# tviic2d6mddr register map
Vendor: Cypress Semiconductor; Series: tviic2d6mddr; File version: 1.0
CPU: CM7 r0p1, little endian, MPU, FPU, VTOR, 3 interrupt priority bits
Registers are 32-bit, read-write, reset 0x0 unless marked. A register's access mark holds for its fields unless they carry their own. Offsets are from the block's base; [hi:lo] are bit positions; lines under a group give offsets from that group; {n}, {i} and the like mark numbered series.

## LPDDR40 (part 3 of 5) — LPDDR4
Base 0x404A0000
0x1000 LPDDR4_CORE group — LPDDR4 core (3PIP)
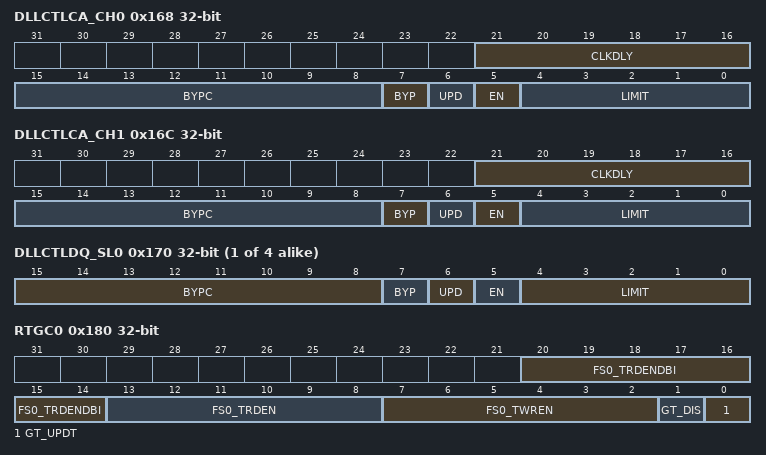
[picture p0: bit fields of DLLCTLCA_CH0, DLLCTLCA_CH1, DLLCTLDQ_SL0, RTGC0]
  0x168 DLLCTLCA_CH0 — DLL Control Register for PHY Command Module - Channel 0
    [21:16] CLKDLY — Phase shifting for mem_clk 6'b000000: No shifted 6'b111111: 0.5 cycle - Channel 0
    [15:8] BYPC — DLL bypass code. - Channel 0
    [7] BYP — DLL bypass enable. - Channel 0 Enable/disable coding: DISABLE = 0 Disable this feature ENABLE = 1 Enable this feature
    [6] UPD — DLL Update. When the PHY is in active operation, DLL update should be turn off. - Channel 0 Enable/disable coding: DISABLE = 0 Disable this feature ENABLE = 1 Enable this feature
    [5] EN — DLL enable. - Channel 0 Enable/disable coding: DISABLE = 0 Disable this feature ENABLE = 1 Enable this feature
    [4:0] LIMIT — Bandwidth for the digital loop. - Channel 0 The recommended value from simulation is 5. The optimum value must be determined from evaluation.
  0x16C DLLCTLCA_CH1 — DLL Control Register for PHY Command Module - Channel 1
    [21:16] CLKDLY — Phase shifting for mem_clk 6'b000000: No shifted 6'b111111: 0.5 cycle - Channel 1
    [15:8] BYPC — DLL bypass code. - Channel 1
    [7] BYP — DLL bypass enable. - Channel 1 Enable/disable coding: DISABLE = 0 Disable this feature ENABLE = 1 Enable this feature
    [6] UPD — DLL Update. When the PHY is in active operation, DLL update should be turn off. - Channel 1 Enable/disable coding: DISABLE = 0 Disable this feature ENABLE = 1 Enable this feature
    [5] EN — DLL enable. - Channel 1 Enable/disable coding: DISABLE = 0 Disable this feature ENABLE = 1 Enable this feature
    [4:0] LIMIT — Bandwidth for the digital loop. - Channel 1 The recommended value from simulation is 5. The optimum value must be determined from evaluation.
  {0x170+4j} DLLCTLDQ_SL{j} (j=0..3) — DLL Control Register for PHY Data Module
    [15:8] BYPC — DLL bypass code.
    [7] BYP — DLL bypass enable. Enable/disable coding: DISABLE = 0 Disable this feature ENABLE = 1 Enable this feature
    [6] UPD — DLL Update. When the PHY is in active operation, DLL update should be turn off. Enable/disable coding: DISABLE = 0 Disable this feature ENABLE = 1 Enable this feature
    [5] EN — DLL enable. Enable/disable coding: DISABLE = 0 Disable this feature ENABLE = 1 Enable this feature
    [4:0] LIMIT — Bandwidth for the digital loop. The recommended value from simulation is 5. The optimum value must be determined from evaluation.
  0x180 RTGC0 — PHY Read Training General Control Register 0
    [20:14] FS0_TRDENDBI — Specifies the number of DFI PHY clock cycles from the assertion of a read command on the DFI to the assertion of the dfi_rddata_en signal in DBI mode
    [13:8] FS0_TRDEN — Specifies the number of DFI PHY clock cycles from the assertion of a read command on the DFI to the assertion of the dfi_rddata_en signal LPDDR4: RL-1
    [7:2] FS0_TWREN — Specifies the number of DFI PHY clock cycles between when a write command is sent on the DFI control interface and when the dfi_wrdata_en signal is asserted. LPDDR4: WL-1
    [1] GT_DIS — Auto gate training disable. This will disable automatic read gate enable. Enable/disable coding: ENABLE = 0 Enable this feature DISABLE = 1 Disable this feature
    [0] GT_UPDT — Gate training setting update Enable/disable coding: DISABLE = 0 Disable this feature ENABLE = 1 Enable this feature
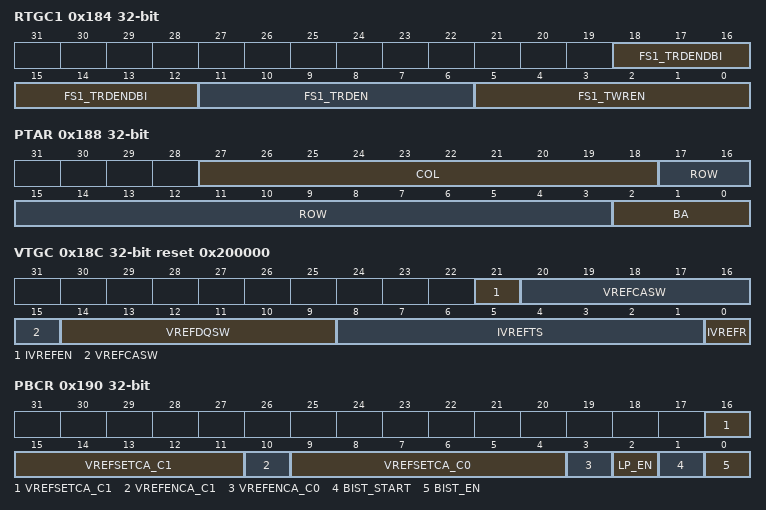
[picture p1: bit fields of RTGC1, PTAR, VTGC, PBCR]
  0x184 RTGC1 — PHY Read Training General Control Register 1
    [18:12] FS1_TRDENDBI — Specifies the number of DFI PHY clock cycles from the assertion of a read command on the DFI to the assertion of the dfi_rddata_en signal in DBI mode
    [11:6] FS1_TRDEN — Specifies the number of DFI PHY clock cycles from the assertion of a read command on the DFI to the assertion of the dfi_rddata_en signal LPDDR4: RL-1
    [5:0] FS1_TWREN — Specifies the number of DFI PHY clock cycles between when a write command is sent on the DFI control interface and when the dfi_wrdata_en signal is asserted. LPDDR4: WL-1
  0x188 PTAR — PHY Sanity Check Address Register
    [27:18] COL — Test column address to be used in Read-Write Sanity Check feature to test Read/Write functions after trainings. This feature is enabled by setting sanchken and phyinit field in POM register.
    [17:3] ROW — Test row address to be used in Read-Write Sanity Check feature to test Read/Write functions after trainings. This feature is enabled by setting sanchken and phyinit field in POM register.
    [2:0] BA — Test bank address to be used in Read-Write Sanity Check feature to test Read/Write functions after trainings. This feature is enabled by setting sanchken and phyinit field in POM register.
  0x18C VTGC reset 0x200000 — PHY VREF Training General Control Register
    [21] IVREFEN — Use Internal PHY VREF. Always set to 1'b1. ENABLE = 1 Always write 1.
    [20:15] VREFCASW — DRAM VREF-CA step width. This field defines the distance between 2 VREF steps in coarse training.
    [14:9] VREFDQSW — DRAM VREF-DQ step width. This field defines the distance between 2 VREF steps in coarse training.
    [8:1] IVREFTS — PHY VREF-DQ training step, specify the number training patterns required by PHY. STEPS64 = 64 Always write 64.
    [0] IVREFR — Internal PHY VREF-DQ range RANGE1 = 1 Always write 1.
  0x190 PBCR — PHY BIST Control Register
    [16:11] VREFSETCA_C1 — VREF setting for control block, in BIST/Loopback mode - Channel B
    [10] VREFENCA_C1 — VREF enable for control block, in BIST/Loopback mode - Channel B Enable/disable coding: DISABLE = 0 Disable this feature ENABLE = 1 Enable this feature
    [9:4] VREFSETCA_C0 — VREF setting for control block, in BIST/Loopback mode - Channel A
    [3] VREFENCA_C0 — VREF enable for control block, in BIST/Loopback mode - Channel A Enable/disable coding: DISABLE = 0 Disable this feature ENABLE = 1 Enable this feature
    [2] LP_EN — PHY Loopback mode enable Enable/disable coding: DISABLE = 0 Disable this feature ENABLE = 1 Enable this feature
    [1] BIST_START — Start PHY BIST mode Enable/disable coding: DISABLE = 0 Disable this feature ENABLE = 1 Enable this feature
    [0] BIST_EN — PHY BIST mode enable Enable/disable coding: DISABLE = 0 Disable this feature ENABLE = 1 Enable this feature
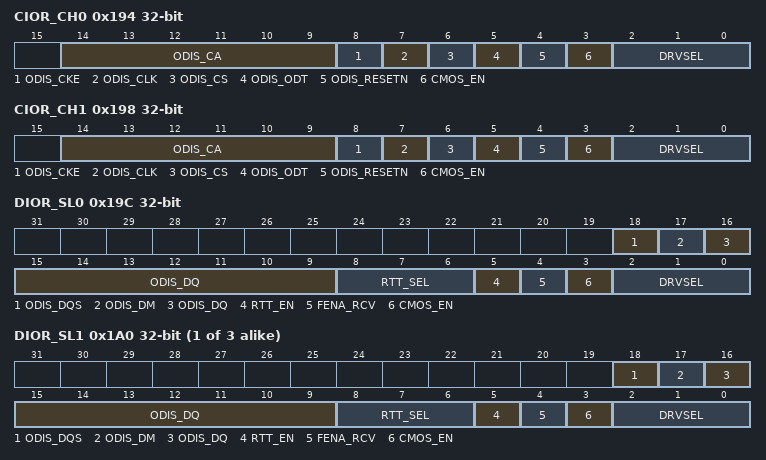
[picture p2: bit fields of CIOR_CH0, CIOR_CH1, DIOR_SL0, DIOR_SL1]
  0x194 CIOR_CH0 — PHY Command Module IO Control Register - Channel 0
    [14:9] ODIS_CA — Channel 0 mem_ca Output Driver Disable. When set to 1, the corresponding output is forced to high-Z. NORMAL = 0 Normal operation FORCE_HIZ = 1 Forced to high-Z
    [8] ODIS_CKE — Channel 0 mem_cke Output Driver Disable. When set to 1, the corresponding output is forced to high-Z. NORMAL = 0 Normal operation FORCE_HIZ = 1 Forced to high-Z
    [7] ODIS_CLK — Channel 0 mem_clk Output Driver Disable. When set to 1, the corresponding output is forced to high-Z. NORMAL = 0 Normal operation FORCE_HIZ = 1 Forced to high-Z
    [6] ODIS_CS — Channel 0 mem_cs Output Driver Disable. When set to 1, the corresponding output is forced to high-Z. NORMAL = 0 Normal operation FORCE_HIZ = 1 Forced to high-Z
    [5] ODIS_ODT — Channel 0 mem_odt Output Driver Disable. When set to 1, the corresponding output is forced to high-Z. NORMAL = 0 Normal operation FORCE_HIZ = 1 Forced to high-Z
    [4] ODIS_RESETN — Channel 0 mem_reset Output Driver Disable. When set to 1, the corresponding output is forced to high-Z. NORMAL = 0 Normal operation FORCE_HIZ = 1 Forced to high-Z
    [3] CMOS_EN — Enable CMOS Receiver in IO - Channel 0 Enable/disable coding: DISABLE = 0 Disable this feature ENABLE = 1 Enable this feature
    [2:0] DRVSEL — 3-bit value to select how many copies of driver need to be turned on. Driver Setting (000-turns on 1 driver copy, 001- 2 driver copy, 010- 3 driver copy, 111- 8 driver copy) - Channel 0 Selects how many copies of drivers are turned on. Number of drivers: DRV1 = 000b 1 driver DRV2 = 001b 2 drivers DRV3 = 010b 3 drivers DRV4 = 011b 4 drivers DRV5 = 100b 5 drivers DRV6 = 101b 6 drivers DRV7 = 110b 7 drivers DRV8 = 111b 8 drivers
  0x198 CIOR_CH1 — PHY Command Module IO Control Register - Channel 1
    [14:9] ODIS_CA — Channel 1 mem_ca Output Driver Disable. When set to 1, the corresponding output is forced to high-Z. NORMAL = 0 Normal operation FORCE_HIZ = 1 Forced to high-Z
    [8] ODIS_CKE — Channel 1 mem_cke Output Driver Disable. When set to 1, the corresponding output is forced to high-Z. NORMAL = 0 Normal operation FORCE_HIZ = 1 Forced to high-Z
    [7] ODIS_CLK — Channel 1 mem_clk Output Driver Disable. When set to 1, the corresponding output is forced to high-Z. NORMAL = 0 Normal operation FORCE_HIZ = 1 Forced to high-Z
    [6] ODIS_CS — Channel 1 mem_cs Output Driver Disable. When set to 1, the corresponding output is forced to high-Z. NORMAL = 0 Normal operation FORCE_HIZ = 1 Forced to high-Z
    [5] ODIS_ODT — Channel 1 mem_odt Output Driver Disable. When set to 1, the corresponding output is forced to high-Z. NORMAL = 0 Normal operation FORCE_HIZ = 1 Forced to high-Z
    [4] ODIS_RESETN — Channel 0 mem_reset Output Driver Disable. When set to 1, the corresponding output is forced to high-Z. NORMAL = 0 Normal operation FORCE_HIZ = 1 Forced to high-Z
    [3] CMOS_EN — Enable CMOS Receiver in IO - Channel 1 Enable/disable coding: DISABLE = 0 Disable this feature ENABLE = 1 Enable this feature
    [2:0] DRVSEL — 3-bit value to select how many copies of driver need to be turned on. Driver Setting (000-turns on 1 driver copy, 001- 2 driver copy, 010- 3 driver copy, 111- 8 driver copy) - Channel 1 Selects how many copies of drivers are turned on. Number of drivers: DRV1 = 000b 1 driver DRV2 = 001b 2 drivers DRV3 = 010b 3 drivers DRV4 = 011b 4 drivers DRV5 = 100b 5 drivers DRV6 = 101b 6 drivers DRV7 = 110b 7 drivers DRV8 = 111b 8 drivers
  0x19C DIOR_SL0 — PHY Data Module IO Control Register
    [18] ODIS_DQS — Data Slice 0 DQS Output Driver Disable. When set to 1, the corresponding output is forced to high-Z. NORMAL = 0 Normal operation FORCE_HIZ = 1 Forced to high-Z
    [17] ODIS_DM — Data Slice 0 DM Output Driver Disable. When set to 1, the corresponding output is forced to high-Z. NORMAL = 0 Normal operation FORCE_HIZ = 1 Forced to high-Z
    [16:9] ODIS_DQ — Data Slice 0 DQ Output Driver Disable. When set to 1, the corresponding output is forced to high-Z. NORMAL = 0 Normal operation FORCE_HIZ = 1 Forced to high-Z
    [8:6] RTT_SEL — Data Slice 0 RTT impedance when rtt_en=1. Values according to JESD209-4: RTT240 = 001b RTT = 240Ohm RTT120 = 010b RTT = 120Ohm RTT80 = 011b RTT = 80Ohm RTT60 = 100b RTT = 60Ohm RTT48 = 101b RTT = 48Ohm RTT40 = 110b RTT = 40Ohm
    [5] RTT_EN — Enable On-Die Termination resistor RTT for slice 0. Enable/disable coding: DISABLE = 0 Disable this feature ENABLE = 1 Enable this feature
    [4] FENA_RCV — PHY Data Module IO Control Register for Slice 0. Driver output enable DRV_TRISTATE = 0 Driver in tristate DRV_ENABLE = 1 Driver enabled FENA_RCV has higher priority than ODIS and OE when it is high. Enable = FENA_RCV + !ODIS & OE
    [3] CMOS_EN — Enable CMOS Receiver in IO Enable/disable coding: DISABLE = 0 Disable this feature ENABLE = 1 Enable this feature
    [2:0] DRVSEL — PHY Data Module IO Control Register Slice 0. Selects how many copies of drivers are turned on. Number of drivers: DRV1 = 000b 1 driver DRV2 = 001b 2 drivers DRV3 = 010b 3 drivers DRV4 = 011b 4 drivers DRV5 = 100b 5 drivers DRV6 = 101b 6 drivers DRV7 = 110b 7 drivers DRV8 = 111b 8 drivers
  {0x19C+4j} DIOR_SL{j} (j=1..3) — PHY Data Module IO Control Register
    [18] ODIS_DQS — Data Slice {j} DQS Output Driver Disable. When set to 1, the corresponding output is forced to high-Z. NORMAL = 0 Normal operation FORCE_HIZ = 1 Forced to high-Z
    [17] ODIS_DM — Data Slice {j} DM Output Driver Disable. When set to 1, the corresponding output is forced to high-Z. NORMAL = 0 Normal operation FORCE_HIZ = 1 Forced to high-Z
    [16:9] ODIS_DQ — Data Slice {j} DQ Output Driver Disable. When set to 1, the corresponding output is forced to high-Z. NORMAL = 0 Normal operation FORCE_HIZ = 1 Forced to high-Z
    [8:6] RTT_SEL — Data Slice {j} RTT impedance when rtt_en=1. Values according to JESD209-4: RTT240 = 001b RTT = 240Ohm RTT120 = 010b RTT = 120Ohm RTT80 = 011b RTT = 80Ohm RTT60 = 100b RTT = 60Ohm RTT48 = 101b RTT = 48Ohm RTT40 = 110b RTT = 40Ohm
    [5] RTT_EN — Enable On-Die Termination resistor RTT for Slice {j}. Enable/disable coding: DISABLE = 0 Disable this feature ENABLE = 1 Enable this feature
    [4] FENA_RCV — PHY Data Module IO Control Register for Slice {j}. Driver output enable DRV_TRISTATE = 0 Driver in tristate DRV_ENABLE = 1 Driver enabled FENA_RCV has higher priority than ODIS and OE when it is high. Enable = FENA_RCV + !ODIS & OE
    [3] CMOS_EN — Enable CMOS Receiver in IO Enable/disable coding: DISABLE = 0 Disable this feature ENABLE = 1 Enable this feature
    [2:0] DRVSEL — PHY Data Module IO Control Register Slice {j}. Selects how many copies of drivers are turned on. Number of drivers: DRV1 = 000b 1 driver DRV2 = 001b 2 drivers DRV3 = 010b 3 drivers DRV4 = 011b 4 drivers DRV5 = 100b 5 drivers DRV6 = 101b 6 drivers DRV7 = 110b 7 drivers DRV8 = 111b 8 drivers
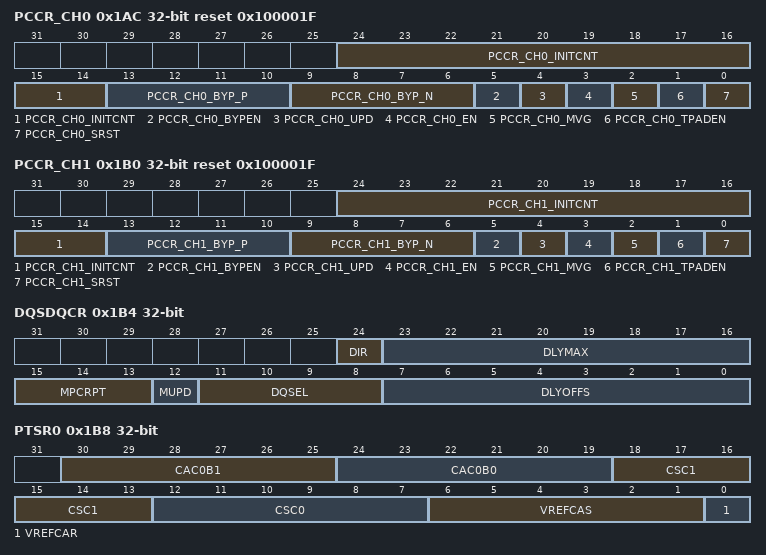
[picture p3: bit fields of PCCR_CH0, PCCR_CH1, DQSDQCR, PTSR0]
  0x1AC PCCR_CH0 reset 0x100001F — PHY Compensation Control Register - Channel 0
    [24:14] PCCR_CH0_INITCNT — Channel 0 PHY compensation initialization counter - Channel 0. Always write 1024.
    [13:10] PCCR_CH0_BYP_P — Bypass setting - Channel 0
    [9:6] PCCR_CH0_BYP_N — Bypass setting - Channel 0
    [5] PCCR_CH0_BYPEN — Bypass internal compensation setting - Channel 0 Enable/disable coding: DISABLE = 0 Disable this feature ENABLE = 1 Enable this feature
    [4] PCCR_CH0_UPD — Update compensation block - Channel 0 Enable/disable coding: DISABLE = 0 Disable this feature ENABLE = 1 Enable this feature
    [3] PCCR_CH0_EN — Enable compensation block - Channel 0 Enable/disable coding: DISABLE = 0 Disable this feature ENABLE = 1 Enable this feature
    [2] PCCR_CH0_MVG — Enable moving average for compensation - Channel 0 Enable/disable coding: DISABLE = 0 Disable this feature ENABLE = 1 Enable this feature
    [1] PCCR_CH0_TPADEN — Testpad enable - Channel 0 Enable/disable coding: DISABLE = 0 Disable this feature ENABLE = 1 Enable this feature
    [0] PCCR_CH0_SRST — Channel 0 Compensation Soft-Reset Compensation soft-reset can be triggered by user's writing 0 to the srst field of the pccr_chX register followed by a writing 1. The srst field must stay at logic 1 indefinitely if user doesn't want to reset the compensation block. Users must poll the field (srstc - Compensation soft-reset complete) in the pcsr_chX register for the ready of the compensation block.
  0x1B0 PCCR_CH1 reset 0x100001F — PHY Compensation Control Register - Channel 1
    [24:14] PCCR_CH1_INITCNT — Channel 1 PHY compensation initialization counter - Channel 0. Always write 1024.
    [13:10] PCCR_CH1_BYP_P — Bypass setting - Channel 1
    [9:6] PCCR_CH1_BYP_N — Bypass setting - Channel 1
    [5] PCCR_CH1_BYPEN — Bypass internal compensation setting - Channel 1 Enable/disable coding: DISABLE = 0 Disable this feature ENABLE = 1 Enable this feature
    [4] PCCR_CH1_UPD — Update compensation block - Channel 1 Enable/disable coding: DISABLE = 0 Disable this feature ENABLE = 1 Enable this feature
    [3] PCCR_CH1_EN — Enable compensation block - Channel 1 Enable/disable coding: DISABLE = 0 Disable this feature ENABLE = 1 Enable this feature
    [2] PCCR_CH1_MVG — Enable moving average for compensation - Channel 1 Enable/disable coding: DISABLE = 0 Disable this feature ENABLE = 1 Enable this feature
    [1] PCCR_CH1_TPADEN — Testpad enable - Channel 1 Enable/disable coding: DISABLE = 0 Disable this feature ENABLE = 1 Enable this feature
    [0] PCCR_CH1_SRST — Channel 1 Compensation Soft-Reset Compensation soft-reset can be triggered by user's writing 0 to the srst field of the pccr_chX register followed by a writing 1. The srst field must stay at logic 1 indefinitely if user doesn't want to reset the compensation block. Users must poll the field (srstc - Compensation soft-reset complete) in the pcsr_chX register for the ready of the compensation block.
  0x1B4 DQSDQCR — DQS2DQ Delay Control Register
    [24] DIR — DQS2DQ retraining direction control: 0: Down - Decrease delay from old setting 1: Up - Increase delay from old setting DOWN = 0 DQS2DQ search downwards UP = 1 DQS2DQ search upwards
    [23:16] DLYMAX — Maximum scan steps for a DQS2DQ training session. Default: 0xFF during PHY Init Training
    [15:13] MPCRPT — Maximum number of consecutive MPC FIFO Write/Read before checking data. Up to 5.
    [12] MUPD — DQS2DQ delay manual update enable. This bit is self-clearing when the delay is updated AUTOMATIC = 0 Automatic update MANUAL = 1 Manual update
    [11:8] DQSEL — Or-select data module to update. Example: 0001: data module 0 0011: data module 0,1 0100: data module 2 1111: data module 0,1,2,3
    [7:0] DLYOFFS — DQS2DQ delay offset (unit of phase based on DRAM clock)
  0x1B8 PTSR0 — PHY Training Setting Register 0
    [30:25] CAC0B1 — CA setting for LPDDR4 channel 0 bit 1
    [24:19] CAC0B0 — CA setting for LPDDR4 channel 0 bit 0
    [18:13] CSC1 — CS setting for LPDDR4 channel 1
    [12:7] CSC0 — CS setting for LPDDR4 channel 0
    [6:1] VREFCAS — VREF-CA setting
    [0] VREFCAR — VREF-CA range VREF Range according to JESD209-4: RANGE0 = 0B Range[0] enabled RANGE1 =1B Range[1] enabled
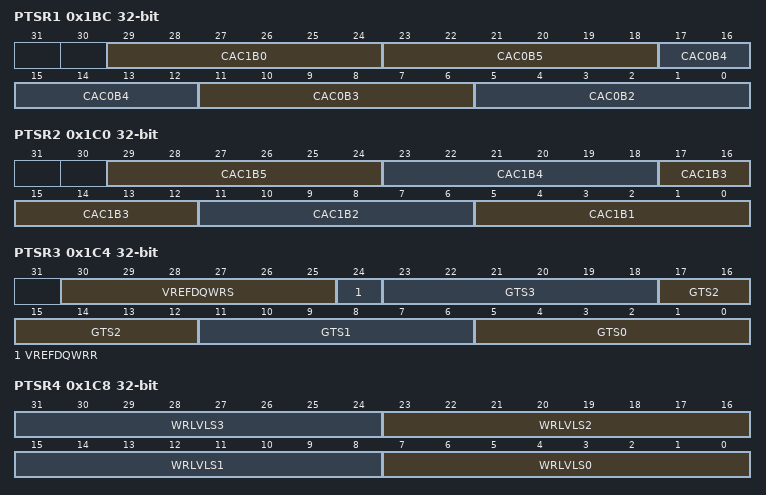
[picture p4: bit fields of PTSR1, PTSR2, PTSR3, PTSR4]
  0x1BC PTSR1 — PHY Training Setting Register 1
    [29:24] CAC1B0 — CA setting for LPDDR4 channel 1 bit 0
    [6n-7:6n-12] CAC0B{n} (n=2..5) — CA setting for LPDDR4 channel 0 bit {n}
  0x1C0 PTSR2 — PHY Training Setting Register 2
    [6n-1:6n-6] CAC1B{n} (n=1..5) — CA setting for LPDDR4 channel 1 bit {n}
  0x1C4 PTSR3 — PHY Training Setting Register 3
    [30:25] VREFDQWRS — VREF-DQ Setting
    [24] VREFDQWRR — VREF-DQ range according to JESD209-4: 0B: VREF(DQ) Range[0] enabled 1B: VREF(DQ) Range[1] enabled
    [6n+5:6n] GTS{n} (n=0..3) — Gate setting for slice {n}
  0x1C8 PTSR4 — PHY Training Setting Register 4
    [8n+7:8n] WRLVLS{n} (n=0..3) — Write leveling setting for slice {n} Bits [6:0] contain the delay setting value. Bit [7] always returns 0 when being read. Always write 0 to Bit [7]. Writing '1' to Bit [7] may cause malfunction of the controller.
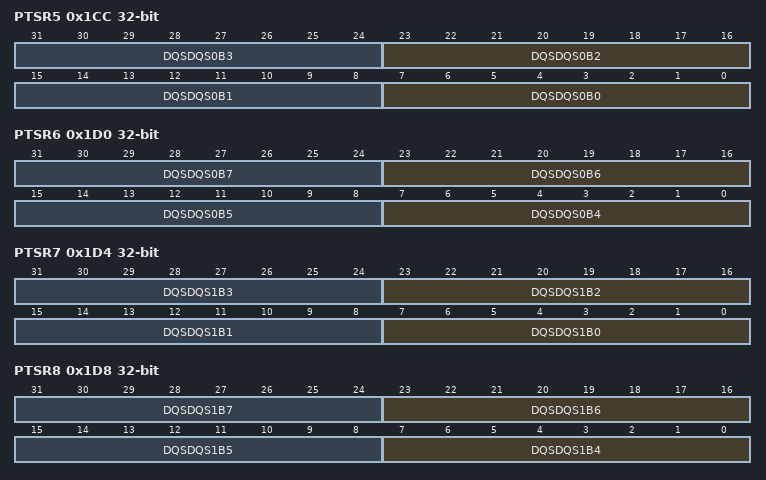
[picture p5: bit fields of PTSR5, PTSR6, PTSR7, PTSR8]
  0x1CC PTSR5 — PHY Training Setting Register 5
    [8n+7:8n] DQSDQS0B{n} (n=0..3) — DQS-DQ setting for slice 0 - DQ[{n}] Bits [6:0] contain the delay setting value. Bit [7] always returns 0 when being read. Always write 0 to Bit [7]. Writing '1' to Bit [7] may cause malfunction of the controller.
  0x1D0 PTSR6 — PHY Training Setting Register 6
    [8n-25:8n-32] DQSDQS0B{n} (n=4..7) — DQS-DQ setting for slice 0 - DQ[{n}] Bits [6:0] contain the delay setting value. Bit [7] always returns 0 when being read. Always write 0 to Bit [7]. Writing '1' to Bit [7] may cause malfunction of the controller.
  0x1D4 PTSR7 — PHY Training Setting Register 7
    [8n+7:8n] DQSDQS1B{n} (n=0..3) — DQS-DQ setting for slice 1 - DQ[{n}] Bits [6:0] contain the delay setting value. Bit [7] always returns 0 when being read. Always write 0 to Bit [7]. Writing '1' to Bit [7] may cause malfunction of the controller.
  0x1D8 PTSR8 — PHY Training Setting Register 8
    [8n-25:8n-32] DQSDQS1B{n} (n=4..7) — DQS-DQ setting for slice 1 - DQ[{n}] Bits [6:0] contain the delay setting value. Bit [7] always returns 0 when being read. Always write 0 to Bit [7]. Writing '1' to Bit [7] may cause malfunction of the controller.
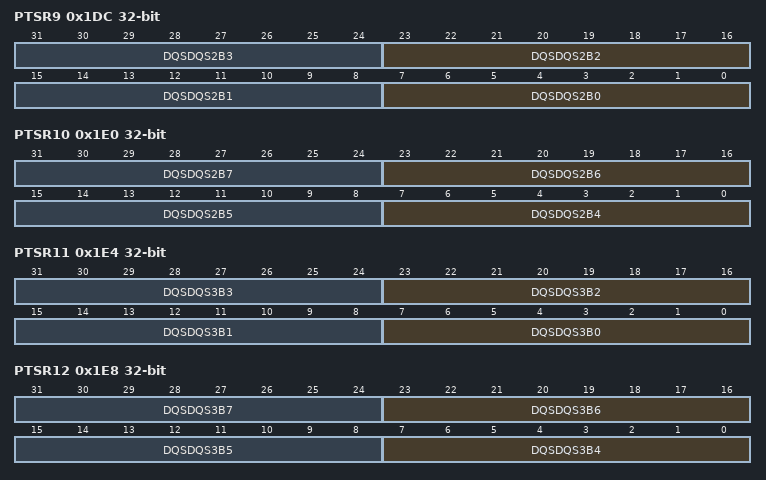
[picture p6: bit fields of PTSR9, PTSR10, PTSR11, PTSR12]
  0x1DC PTSR9 — PHY Training Setting Register 9
    [8n+7:8n] DQSDQS2B{n} (n=0..3) — DQS-DQ setting for slice 2 - DQ[{n}] Bits [6:0] contain the delay setting value. Bit [7] always returns 0 when being read. Always write 0 to Bit [7]. Writing '1' to Bit [7] may cause malfunction of the controller.
  0x1E0 PTSR10 — PHY Training Setting Register 10
    [8n-25:8n-32] DQSDQS2B{n} (n=4..7) — DQS-DQ setting for slice 2 - DQ[{n}] Bits [6:0] contain the delay setting value. Bit [7] always returns 0 when being read. Always write 0 to Bit [7]. Writing '1' to Bit [7] may cause malfunction of the controller.
  0x1E4 PTSR11 — PHY Training Setting Register 11
    [8n+7:8n] DQSDQS3B{n} (n=0..3) — DQS-DQ setting for slice 3 - DQ[{n}] Bits [6:0] contain the delay setting value. Bit [7] always returns 0 when being read. Always write 0 to Bit [7]. Writing '1' to Bit [7] may cause malfunction of the controller.
  0x1E8 PTSR12 — PHY Training Setting Register 12
    [8n-25:8n-32] DQSDQS3B{n} (n=4..7) — DQS-DQ setting for slice 3 - DQ[{n}] Bits [6:0] contain the delay setting value. Bit [7] always returns 0 when being read. Always write 0 to Bit [7]. Writing '1' to Bit [7] may cause malfunction of the controller.
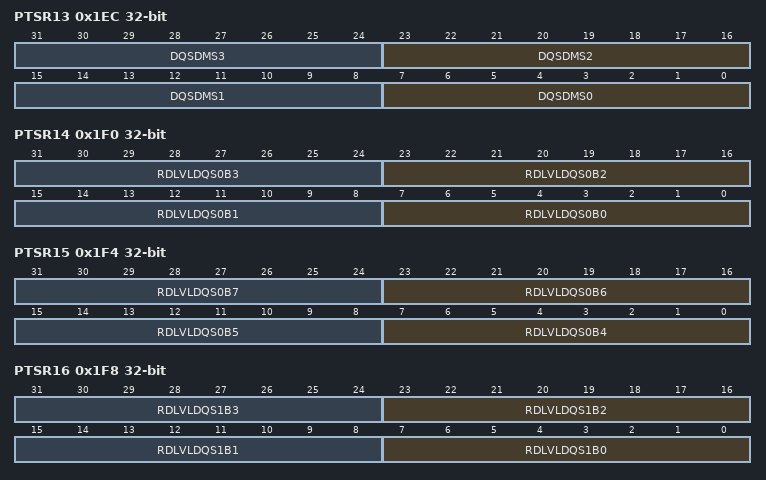
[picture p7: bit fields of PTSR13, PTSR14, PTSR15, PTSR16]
  0x1EC PTSR13 — PHY Training Setting Register 13
    [8n+7:8n] DQSDMS{n} (n=0..3) — DQS-DM setting for slice {n} Bits [6:0] contain the delay setting value. Bit [7] always returns 0 when being read. Always write 0 to Bit [7]. Writing '1' to Bit [7] may cause malfunction of the controller.
  0x1F0 PTSR14 — PHY Training Setting Register 14
    [8n+7:8n] RDLVLDQS0B{n} (n=0..3) — Read DQ setting for slice 0 bit {n} Bits [6:0] contain the delay setting value. Bit [7] always returns 0 when being read. Always write 0 to Bit [7]. Writing '1' to Bit [7] may cause malfunction of the controller.
  0x1F4 PTSR15 — PHY Training Setting Register 15
    [8n-25:8n-32] RDLVLDQS0B{n} (n=4..7) — Read DQ setting for slice 0 bit {n} Bits [6:0] contain the delay setting value. Bit [7] always returns 0 when being read. Always write 0 to Bit [7]. Writing '1' to Bit [7] may cause malfunction of the controller.
  0x1F8 PTSR16 — PHY Training Setting Register 16
    [8n+7:8n] RDLVLDQS1B{n} (n=0..3) — Read DQ setting for slice 1 bit {n} Bits [6:0] contain the delay setting value. Bit [7] always returns 0 when being read. Always write 0 to Bit [7]. Writing '1' to Bit [7] may cause malfunction of the controller.
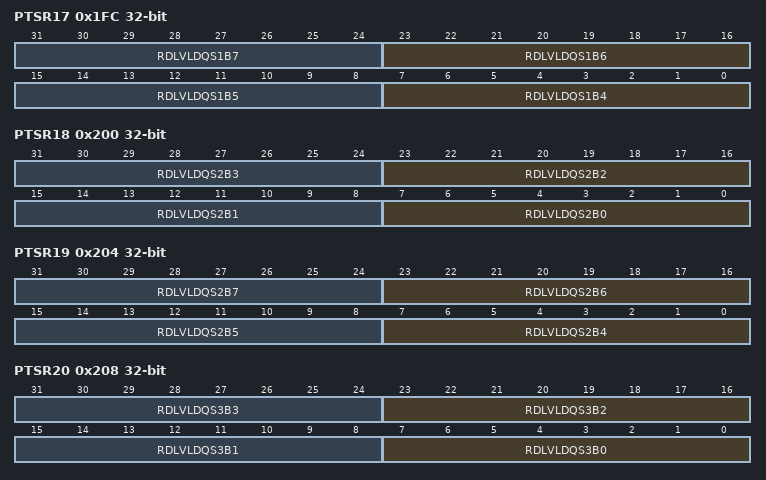
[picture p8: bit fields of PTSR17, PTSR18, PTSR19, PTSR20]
  0x1FC PTSR17 — PHY Training Setting Register 17
    [8n-25:8n-32] RDLVLDQS1B{n} (n=4..7) — Read DQ setting for slice 1 bit {n} Bits [6:0] contain the delay setting value. Bit [7] always returns 0 when being read. Always write 0 to Bit [7]. Writing '1' to Bit [7] may cause malfunction of the controller.
  0x200 PTSR18 — PHY Training Setting Register 18
    [8n+7:8n] RDLVLDQS2B{n} (n=0..3) — Read DQ setting for slice 2 bit {n} Bits [6:0] contain the delay setting value. Bit [7] always returns 0 when being read. Always write 0 to Bit [7]. Writing '1' to Bit [7] may cause malfunction of the controller.
  0x204 PTSR19 — PHY Training Setting Register 19
    [8n-25:8n-32] RDLVLDQS2B{n} (n=4..7) — Read DQ setting for slice 2 bit {n} Bits [6:0] contain the delay setting value. Bit [7] always returns 0 when being read. Always write 0 to Bit [7]. Writing '1' to Bit [7] may cause malfunction of the controller.
  0x208 PTSR20 — PHY Training Setting Register 20
    [8n+7:8n] RDLVLDQS3B{n} (n=0..3) — Read DQ setting for slice 3 bit {n} Bits [6:0] contain the delay setting value. Bit [7] always returns 0 when being read. Always write 0 to Bit [7]. Writing '1' to Bit [7] may cause malfunction of the controller.
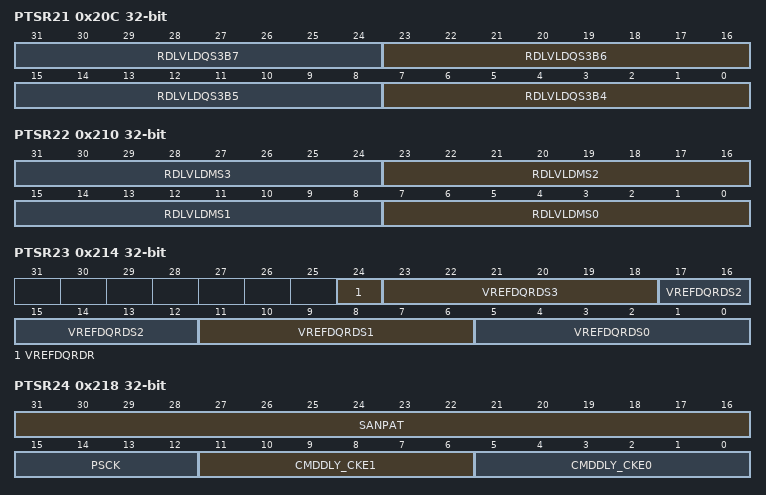
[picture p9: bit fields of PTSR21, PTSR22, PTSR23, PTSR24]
  0x20C PTSR21 — PHY Training Setting Register 21
    [8n-25:8n-32] RDLVLDQS3B{n} (n=4..7) — Read DQ setting for slice 3 bit {n} Bits [6:0] contain the delay setting value. Bit [7] always returns 0 when being read. Always write 0 to Bit [7]. Writing '1' to Bit [7] may cause malfunction of the controller.
  0x210 PTSR22 — PHY Training Setting Register 22
    [8n+7:8n] RDLVLDMS{n} (n=0..3) — Read DM setting for slice {n} Bits [6:0] contain the delay setting value. Bit [7] always returns 0 when being read. Always write 0 to Bit [7]. Writing '1' to Bit [7] may cause malfunction of the controller.
  0x214 PTSR23 — PHY Training Setting Register 23
    [24] VREFDQRDR — VREF-DQ range for READ path
    [6n+5:6n] VREFDQRDS{n} (n=0..3) — VREF-DQ setting for slice {n} READ path
  0x218 PTSR24 — PHY Training Setting Register 24
    [31:16] SANPAT — Sanity check pattern. Each of 16 bits sanpat[15:0] is used for one data transfer. Therefore, 16 bits sanpat[15:0] correspond to one DRAM burst (LPDDR4 - BL16). The values of all bits in a data transfer are the same and equal to sanpat bit of corresponding transfer.
    [15:12] PSCK — PHY-set 1CK exceed for each slice
    [11:6] CMDDLY_CKE1 — MEM_CKE[1] delay setting
    [5:0] CMDDLY_CKE0 — MEM_CKE[0] delay setting
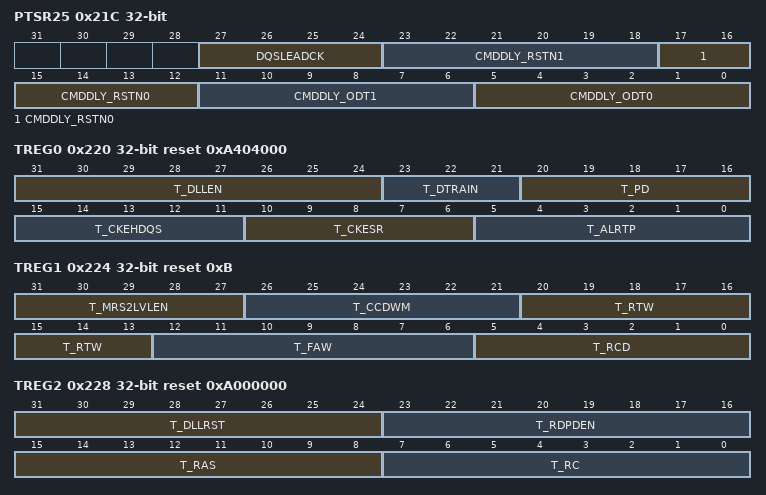
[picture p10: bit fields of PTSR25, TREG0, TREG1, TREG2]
  0x21C PTSR25 — PHY Training Setting Register 25
    [27:24] DQSLEADCK — Rank 0 DQS leads CK flag. One bit for each slice. 0: CK leads DQS, 1: DQS leads CK.
    [23:18] CMDDLY_RSTN1 — MEM_RESET_N[1] delay setting
    [17:12] CMDDLY_RSTN0 — MEM_RESET_N[0] delay setting
    [11:6] CMDDLY_ODT1 — MEM_ODT[1] of MEM_ODT delay setting
    [5:0] CMDDLY_ODT0 — MEM_ODT[0] of MEM_ODT delay setting
  0x220 TREG0 reset 0xA404000 — Timing Register 0
    [31:24] T_DLLEN — DLL enable time. Number of DTI_CLOCK that the DLL_EN must be asserted before DLL_RESET can be asserted. Always write 10.
    [23:21] T_DTRAIN — tDStrain and tDHtrain = tDtrain
    [20:16] T_PD — Power Down Entry to Exit Timing = tCKE
    [15:11] T_CKEHDQS — CKE high to DQS = tCKEHDQS + 12
    [10:6] T_CKESR — Minimum Self Refresh Time (Entry to Exit) = tSR
    [5:0] T_ALRTP — Internal READ Command to PRECHARGE Command delay = tRTP + BL/2 - 12
  0x224 TREG1 reset 0xB — Timing Register 1
    [31:27] T_MRS2LVLEN — MRS leveling enable to leveling enable = tWLDQSEN + 5
    [26:21] T_CCDWM — CAS_n to CAS_n command delay for Masked Write = tCCDMW = 32
    [20:13] T_RTW — Read to Write Command Latency (Bus Turnaround) = RL + BL/2 - WL +3
    [12:6] T_FAW — Four activate window = tFAW - 4
    [5:0] T_RCD — ACT to internal read or write delay time = tRCD - 4
  0x228 TREG2 reset 0xA000000 — Timing Register 2
    [31:24] T_DLLRST — DLL reset time. The number of DTI_CLOCKs for which the DLL_RESET must remain asserted when reset is triggered though the POM register. Always write 10.
    [23:16] T_RDPDEN — Timing of RD/RDA command to Power Down entry = RL + BL/2 +1
    [15:8] T_RAS — ACTIVE to PRECHARGE command period = tRAS_min - 4
    [7:0] T_RC — ACT to ACT or REF command period = tRC - 8
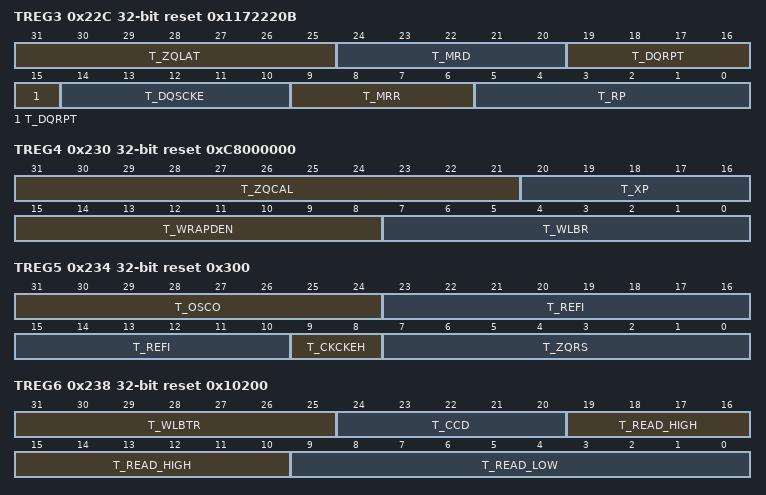
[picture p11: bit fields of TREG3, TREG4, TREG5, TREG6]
  0x22C TREG3 reset 0x1172220B — Timing Register 3
    [31:25] T_ZQLAT — ZQ latch time = tZQLAT
    [24:20] T_MRD — Mode Register Set command cycle time = tMRD + 4
    [19:15] T_DQRPT — This field defines the number of consecutive times of reading data correctly to confirm the stability of DRAM read before DQS2DQ training finishes = 8.
    [14:10] T_DQSCKE — Valid Strobe Requirement before CKE Low = tDQSCKE
    [9:6] T_MRR — Mode Register Read register = tMRR
    [5:0] T_RP — PRE command period = tRP -4
  0x230 TREG4 reset 0xC8000000 — Timing Register 4
    [31:21] T_ZQCAL — ZQ calibration time = tZQCAL
    [20:16] T_XP — Exit Power Down with DLL on to any valid command; Exit Precharge Power Down with DLL frozen to commands not requiring a locked DLL = tXP
    [15:8] T_WRAPDEN — Timing of WRA command to Power Down entry = WL + BL/2 +tWR +2
    [7:0] T_WLBR — = WL + BL/2 - 3 + tWR
  0x234 TREG5 reset 0x300 — Timing Register 5
    [31:24] T_OSCO — Delay time from OSC stop to Mode Register Readout = tOSCO
    [23:10] T_REFI — Average periodic refresh interval = tREFI
    [9:8] T_CKCKEH — CK to CKE high = tCKCKEH
    [7:0] T_ZQRS — ZQ Calibration Reset time = tZQRESET
  0x238 TREG6 reset 0x10200 — Timing Register 6
    [31:25] T_WLBTR — Delay from start of internal write transaction to internal read command - Different BG. = WL + BL/2 + tWTR+1
    [24:20] T_CCD — CAS_n to CAS_n command delay (min = BL/2) = tCCD
    [19:10] T_READ_HIGH — Maximum number of cycles that a high priority read can wait before initiating the direction switch = 64
    [9:0] T_READ_LOW — Maximum number of cycles that a low priority read can wait before initiating the direction switch = 512
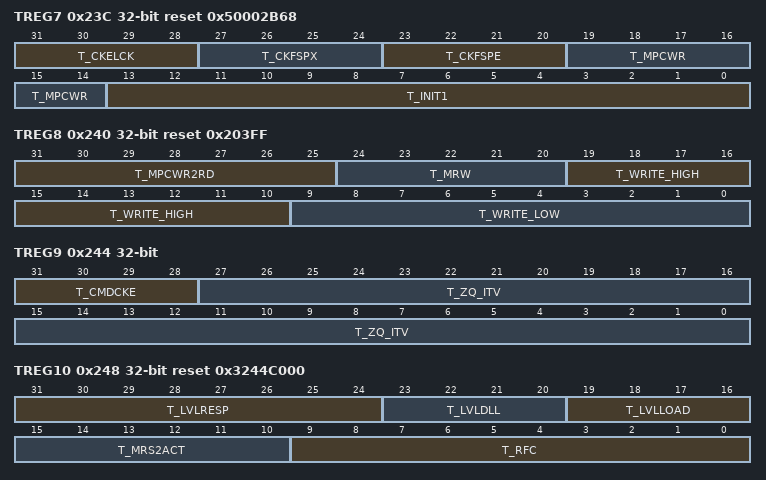
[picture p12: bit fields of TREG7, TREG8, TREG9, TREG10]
  0x23C TREG7 reset 0x50002B68 — Timing Register 7
    [31:28] T_CKELCK — CKE low to CK = tCKELCK
    [27:24] T_CKFSPX — Valid Clock Requirement before 1st Valid Command after FSP change (tCK: 625ps) = tCKFSPX
    [23:20] T_CKFSPE — Valid clock requirement after entering FSP change = tCKFSPE
    [19:14] T_MPCWR — Additional time after tXP has expired until MPC [WRITE FIFO] command may be issued = tRCD + 3
    [13:0] T_INIT1 — Minimum RESET_n LOW time after completion of voltage ramp = tINIT1
  0x240 TREG8 reset 0x203FF — Timing Register 8
    [31:25] T_MPCWR2RD — MPC write fifo to MPC read fifo = WL + BL/2 + 1 + tWTR
    [24:20] T_MRW — Mode Register Write command period. = tMRW
    [19:10] T_WRITE_HIGH — Maximum number of cycles that a high priority write can wait before initiating the direction switch = 64
    [9:0] T_WRITE_LOW — Maximum number of cycles that a low priority write can wait before initiating the direction switch = 512
  0x244 TREG9 — Timing Register 9
    [31:28] T_CMDCKE — Delay from valid command to CKE input LOW = tCMDCKE
    [27:0] T_ZQ_ITV — Auto ZQ Calibration interval in case DMCFG.ZQ_AUTO_EN = 1.
  0x248 TREG10 reset 0x3244C000 — Timing Register 10
    [31:24] T_LVLRESP — Leveling response latency. Specifies the maximum number of DFI clock cycles from the assertion of a read or mode register read command to the guaranteed validity of the response signal. = 90
    [23:20] T_LVLDLL — DLL delay. Specifies the minimum number of DFI clock cycles from when DTI_*_LOAD signal updates the DLL delay in the appropriate DTI_*_DLY to when the PHY is ready for the next read or mode register read command. = 15
    [19:16] T_LVLLOAD — Delay settling time. Specifies the minimum number of DFI clock cycles from when the delays are loaded on the DTI_*_DLY signal to when the DTI_*_LOAD signal may be asserted. = 8
    [15:10] T_MRS2ACT — MRW leveling enable to load pulse = tWLMRD + 10
    [9:0] T_RFC — Refresh Cycle Time (All Banks) = tRFCab - 4
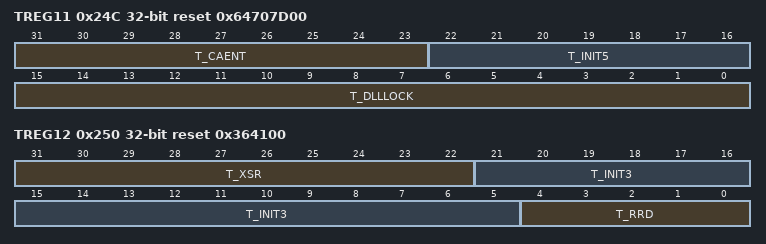
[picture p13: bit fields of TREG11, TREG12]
  0x24C TREG11 reset 0x64707D00 — Timing Register 11
    [31:23] T_CAENT — First CA Bus Training Command Following CKE Low = tCAENT
    [22:16] T_INIT5 — Minimum idle time before first MRW/MRR command = tINIT5
    [15:0] T_DLLLOCK — DLL lock timeout. The number of DTI_CLOCKs from when the DLL reset is de-asserted to when the DLL is locked and ready for use = 'h7d00
  0x250 TREG12 reset 0x364100 — Timing Register 12
    [31:22] T_XSR — Self refresh exit to next valid command delay. = tXSR
    [21:5] T_INIT3 — Minimum CKE LOW time after RESET_n goes HIGH = tINIT3
    [4:0] T_RRD — ACTIVATE to ACTIVATE Command delay = tRRD
